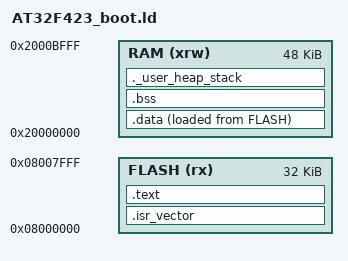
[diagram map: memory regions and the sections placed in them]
ENTRY(Reset_Handler)
_estack = 0x2000C000;
_Min_Heap_Size = 0x100;
_Min_Stack_Size = 0x800;
MEMORY
{
  FLASH (rx)  : ORIGIN = 0x08000000, LENGTH = 32K
  RAM (xrw)   : ORIGIN = 0x20000000, LENGTH = 48K
}
SECTIONS
{
  .isr_vector :
  {
    . = ALIGN(4);
    KEEP(*(.isr_vector))
    . = ALIGN(4);
  } > FLASH
  .text :
  {
    . = ALIGN(4);
    *(.text)
    *(.text*)
    *(.rodata)
    *(.rodata*)
    *(.glue_7)
    *(.glue_7t)
    KEEP(*(.init))
    KEEP(*(.fini))
    . = ALIGN(4);
    _etext = .;
  } > FLASH
  _sidata = LOADADDR(.data);
  .data :
  {
    . = ALIGN(4);
    _sdata = .;
    *(.data)
    *(.data*)
    . = ALIGN(4);
    _edata = .;
  } > RAM AT > FLASH
  .bss :
  {
    . = ALIGN(4);
    _sbss = .;
    *(.bss)
    *(.bss*)
    *(COMMON)
    . = ALIGN(4);
    _ebss = .;
  } > RAM
  ._user_heap_stack :
  {
    . = ALIGN(8);
    . = . + _Min_Heap_Size;
    . = . + _Min_Stack_Size;
    . = ALIGN(8);
  } > RAM
  /DISCARD/ : { libc.a(*) libm.a(*) libgcc.a(*) }
  .ARM.attributes 0 : { *(.ARM.attributes) }
}
